# SN32F700 register map
Vendor: SONiX Technology Co., Ltd.; Series: SN32F700; File version: 1.9
CPU: CM0 r0p0, little endian, no MPU, no FPU, 2 interrupt priority bits
Registers are 32-bit, read-write, reset 0x0 unless marked. A register's access mark holds for its fields unless they carry their own. Offsets are from the block's base; [hi:lo] are bit positions; {n}, {i} and the like mark numbered series.

## SN_RTC — Real-time Clock
Base 0x40012000
0x00 CTRL — Offset:0x00 RTC Control Register
  [0] RTCEN — RTC enable
    0=Disable RTC; 1=Enable RTC
0x04 CLKS — Offset:0x04 RTC Clock Source Register
  [1:0] CLKSEL — RTC clock source
    0=ILRC (ILRC is RTC clock source); 1=ELS XTAL (ELS Xtal is RTC clock source); 3=EHS XTAL clock/128 (EHS Xtal/128 is RTC clock source)
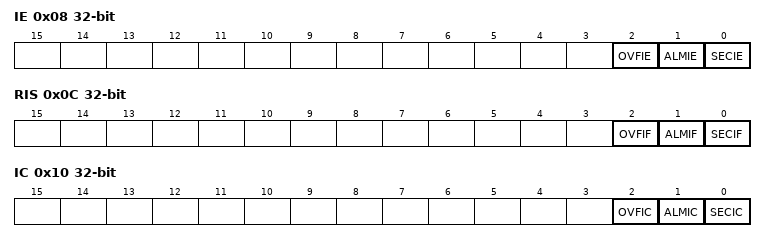
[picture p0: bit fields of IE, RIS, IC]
0x08 IE — Offset:0x08 RTC Interrupt Enable Register
  [2] OVFIE — Overflow interrupt enable
    0=Disable overflow interrupt; 1=Enable overflow interrupt
  [1] ALMIE — Alarm interrupt enable
    0=Disable alarm interrupt; 1=Enable alarm interrupt
  [0] SECIE — Second interrupt enable
    0=Disable second interrupt; 1=Enable second interrupt
0x0C RIS ro — Offset:0x0C RTC Raw Interrupt Status Register
  [2] OVFIF — Overflow interrupt flag
    0=No (No overflow interrupt); 1=Met overflow interrupt requirements (Overflow interrupt is triggered when OVFIE=1)
  [1] ALMIF — Alarm interrupt flag
    0=No (No alarm interrupt); 1=Met alarm interrupt requirements (Alarm interrupt is triggered when ALMIE=1)
  [0] SECIF — Second interrupt flag
    0=No (No second interrupt); 1=Met second interrupt requirements (Second interrupt is triggered when SECIE=1)
0x10 IC wo — Offset:0x10 RTC Interrupt Clear Register
  [2] OVFIC — Overflow interrupt flag clear
    0=No effect; 1=Clear overflow interrupt flag
  [1] ALMIC — Alarm interrupt flag clear
    0=No effect; 1=Clear alarm interrupt flag
  [0] SECIC — Second interrupt flag clear
    0=No effect; 1=Clear second interrupt flag
0x14 SECCNTV reset 0x8000 (reset mask 0xFFFFF) — Offset:0x14 RTC Second Counter Reload Value Register
0x18 SECCNT ro — Offset:0x18 RTC Second Counter Register
0x1C ALMCNTV reset 0xFFFFFFFF — Offset:0x1C RTC Alarm Counter Reload Value Register
0x20 ALMCNT ro — Offset:0x20 RTC Alarm Counter Register

## SN_PMU — Power Management Unit
Base 0x40032000
{0x0+4i} BKP{i} (i=0..15) — Offset:{0x0+4i} PMU Backup Register {i}
  [7:0] BACKUPDATA — Data retained during Deep power-down mode
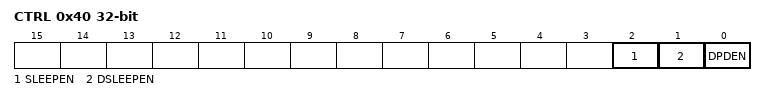
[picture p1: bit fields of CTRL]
0x40 CTRL — Offset:0x40 PMU Control Register
  [2] SLEEPEN — Sleep mode Enable
    0=Disable (No effect); 1=Enable (WFI instruction will make MCU enter Sleep mode)
  [1] DSLEEPEN — Deep Sleep mode Enable
    0=Disable (No effect); 1=Enable (WFI instruction will make MCU enter Deep-sleep mode)
  [0] DPDEN — Deep Power-down mode Enable
    0=Disable (No effect); 1=Enable (WFI instruction will make MCU enter Deep Power-down mode)

## SN_I2C0 — I2C0
Base 0x40018000
Same registers: SN_I2C1 0x4005A000
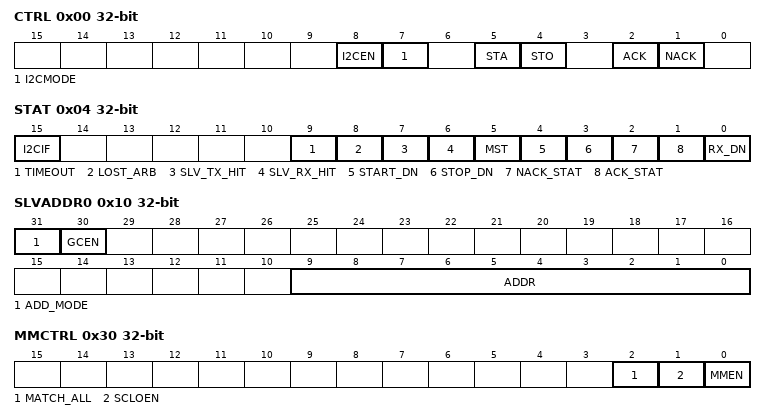
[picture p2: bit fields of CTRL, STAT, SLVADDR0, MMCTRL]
0x00 CTRL — Offset:0x00 I2Cn Control Register
  [8] I2CEN — I2Cn interface enable
    0=Disable I2C; 1=Enable I2C
  [7] I2CMODE
    0=Standard/Fast mode
  [5] STA — START assert flag
    0=No action (No START condition or Repeated START condition will be generated); 1=Assert (Enter master mode and transmit a START or Repeated START condition)
  [4] STO — STOP assert flag
    0=Idle (STOP condition idle); 1=Assert (Transmit a STOP condition in master mode, or recover from an error condition in slave mode)
  [2] ACK — ACK assert flag
    0=No (Master: No action/Slave: Assert NACK after receiving); 1=Assert ACK during the acknowledge clock pulse on SCLn
  [1] NACK — NACK assert flag
    0=No action; 1=Assert NACK during the acknowledge clock pulse on SCLn
0x04 STAT — Offset:0x04 I2Cn Status Register
  [15] I2CIF — I2C interrupt flag
    0=I2C status doesn't change; 1=I2C status changes
  [9] TIMEOUT ro — Time-out status
    0=No timeout; 1=Timeout
  [8] LOST_ARB ro — Lost arbitration status
    0=Not lost arbitration; 1=Lost arbitration
  [7] SLV_TX_HIT ro — Slave TX address hit flag
    0=No matched slave address; 1=Slave address hit, and is called for TX
  [6] SLV_RX_HIT ro — Slave RX address hit flag
    0=No matched slave address; 1=Slave address hit, and is called for RX
  [5] MST ro — I2C master/slave status
    0=Slave (Act as Slave); 1=Master (Act as Master)
  [4] START_DN ro — START done status
    0=No (No START condition); 1=Assert (Transmit or receive a START condition)
  [3] STOP_DN ro — STOP done status
    0=No (No STOP condition); 1=Done (Transmit or receive a STOP condition)
  [2] NACK_STAT ro — NACK done status
    0=No (No NACK received); 1=Done (Receive a NACK)
  [1] ACK_STAT ro — ACK done status
    0=No (No ACK received); 1=Done (Receive an ACK)
  [0] RX_DN ro — RX done status
    0=Not done (No RX with ACK/NACK transfer); 1=Done (8-bit RX with ACK/NACK transfer)
0x08 TXDATA — Offset:0x08 I2Cn TX Data Register
  [7:0] Data — TX Data
0x0C RXDATA ro — Offset:0x0C I2Cn RX Data Register
  [7:0] Data — RX Data received when RX_DN=1
0x10 SLVADDR0 — Offset:0x10 I2Cn Slave Address 0 Register
  [31] ADD_MODE — Slave address mode
    0=7-bit slave address mode; 1=10-bit slave address mode
  [30] GCEN — General call address enable
    0=Disable general call address; 1=Enable general call address (0x0)
  [9:0] ADDR — I2Cn slave address 0
{0x10+4i} SLVADDR{i} (i=1..3) — Offset:{0x10+4i} I2Cn Slave Address {i} Register
  [9:0] ADDR — I2Cn slave address {i}
0x20 SCLHT reset 0x4 — Offset:0x20 I2Cn SCL High Time Register
  [7:0] SCLH — SCLn High period time=(SCLHT+1)*I2Cn_PCLK cycle
0x24 SCLLT reset 0x4 — Offset:0x24 I2Cn SCL Low Time Register
  [7:0] SCLL — SCLn Low period time=(SCLLT+1)*I2Cn_PCLK cycle
0x2C TOCTRL — Offset:0x2C I2Cn Timeout Control Register
  [15:0] TO — Timeout period time = TO*32*I2Cn_PCLK cycle
0x30 MMCTRL — Offset:0x30 I2Cn Monitor Mode Control Register
  [2] MATCH_ALL — Match address selection
    0=I2Cn_SLVADDR0~3 (Interrupt will only be generated when the address matches one of the I2Cn_SLVADDR0~3 register); 1=All (Interrupt will be generated on ANY address received if in monitor mode)
  [1] SCLOEN — SCLn output enable
    0=Disable SCLn output, SCLn is forced High; 1=Enable (I2C module may hold the SCLn Low until it has time to respond to an I2C interrupt)
  [0] MMEN — Monitor mode enable
    0=Disable monitor mode; 1=Enable monitor mode

## SN_FLASH — FLASH Memory Control Registers
Base 0x40062000
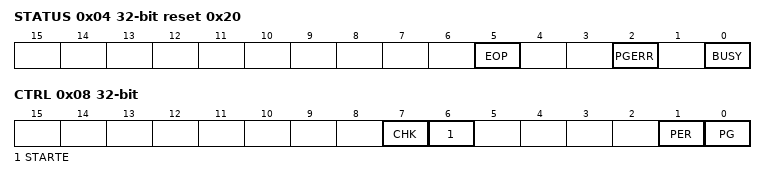
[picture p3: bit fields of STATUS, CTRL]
0x04 STATUS reset 0x20 — Offset:0x04 Flash Status Register
  [5] EOP — End of process flag
    0=Busy (Flash operation is not completed); 1=End (Flash operation is completed)
  [2] PGERR — Program error flag
    0=No error; 1=Program error (The address to be programmed contains a value different from 0xFFFF)
  [0] BUSY ro — Busy flag
    0=Idle (Flash operation is stopped.); 1=Busy (Flash operation is in process)
0x08 CTRL — Offset:0x08 Flash Control Register
  [7] CHK — Checksum calculation chosen
    0=Disable; 1=Enable (Trigger Checksum calculation)
  [6] STARTE — Start erase operation
    0=Stop/Finish (Erase operation is finished.); 1=Start erase operation
  [1] PER — Page erase choosen
    0=Not chosen (Not choose page erase operation.); 1=Choose page erase operation
  [0] PG — Flash program choosen
    0=Not chosen (Not choose Flash program operation.); 1=Choose Flash program operation
0x0C DATA — Offset:0x0C Flash Data Register
0x10 ADDR — Offset:0x10 Flash Address Register
0x14 CHKSUM ro (reset mask 0xFFFF) — Offset:0x14 Flash Checksum Register

## SN_UC — UC Registers
Base 0x1FFF221C
0x00 L4BYTE ro — Offset:0x00 UC Low 4 Byte Register
0x04 H4BYTE ro — Offset:0x04 UC High 4 Byte Register
